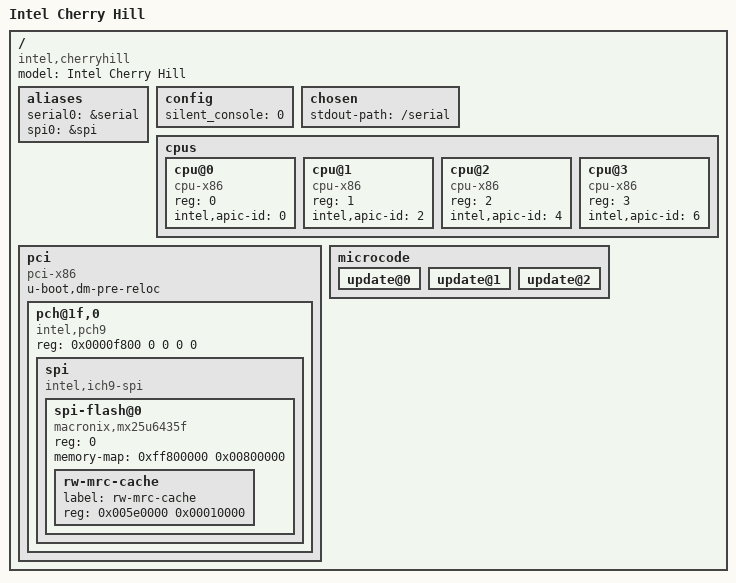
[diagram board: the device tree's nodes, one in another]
/*
 * Copyright (C) 2016, Bin Meng <bmeng.cn@gmail.com>
 *
 * SPDX-License-Identifier:	GPL-2.0+
 */

/dts-v1/;

/include/ "skeleton.dtsi"
/include/ "serial.dtsi"
/include/ "rtc.dtsi"
/include/ "tsc_timer.dtsi"

/ {
	model = "Intel Cherry Hill";
	compatible = "intel,cherryhill", "intel,braswell";

	aliases {
		serial0 = &serial;
		spi0 = &spi;
	};

	config {
		silent_console = <0>;
	};

	chosen {
		stdout-path = "/serial";
	};

	cpus {
		#address-cells = <1>;
		#size-cells = <0>;

		cpu@0 {
			device_type = "cpu";
			compatible = "cpu-x86";
			reg = <0>;
			intel,apic-id = <0>;
		};

		cpu@1 {
			device_type = "cpu";
			compatible = "cpu-x86";
			reg = <1>;
			intel,apic-id = <2>;
		};

		cpu@2 {
			device_type = "cpu";
			compatible = "cpu-x86";
			reg = <2>;
			intel,apic-id = <4>;
		};

		cpu@3 {
			device_type = "cpu";
			compatible = "cpu-x86";
			reg = <3>;
			intel,apic-id = <6>;
		};
	};

	pci {
		compatible = "pci-x86";
		#address-cells = <3>;
		#size-cells = <2>;
		u-boot,dm-pre-reloc;
		ranges = <0x02000000 0x0 0x80000000 0x80000000 0 0x40000000
			  0x42000000 0x0 0xc0000000 0xc0000000 0 0x20000000
			  0x01000000 0x0 0x2000 0x2000 0 0xe000>;

		pch@1f,0 {
			reg = <0x0000f800 0 0 0 0>;
			compatible = "intel,pch9";
			#address-cells = <1>;
			#size-cells = <1>;

			spi: spi {
				#address-cells = <1>;
				#size-cells = <0>;
				compatible = "intel,ich9-spi";

				spi-flash@0 {
					#address-cells = <1>;
					#size-cells = <1>;
					reg = <0>;
					compatible = "macronix,mx25u6435f", "spi-flash";
					memory-map = <0xff800000 0x00800000>;
					rw-mrc-cache {
						label = "rw-mrc-cache";
						reg = <0x005e0000 0x00010000>;
					};
				};
			};
		};
	};

	microcode {
		update@0 {
#include "microcode/m01406c2220.dtsi"
		};
		update@1 {
#include "microcode/m01406c3363.dtsi"
		};
		update@2 {
#include "microcode/m01406c440a.dtsi"
		};
	};

};
